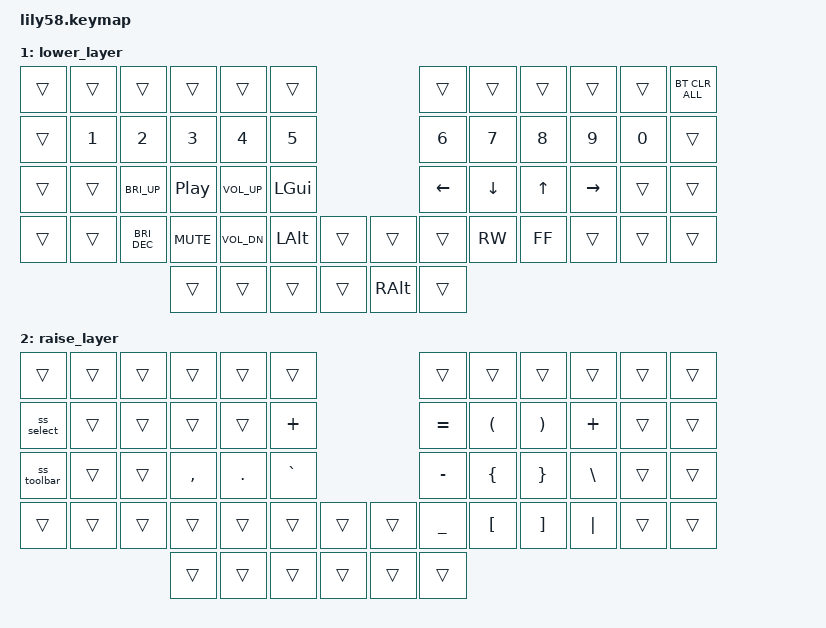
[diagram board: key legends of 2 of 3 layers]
/*
 * Lily58 keymap ported 1:1 from Corne
 */

#include <behaviors.dtsi>
#include <dt-bindings/zmk/bt.h>
#include <dt-bindings/zmk/keys.h>

/ {
    macros {
        ss_full: ss_full {
            compatible = "zmk,behavior-macro";
            label = "SS_FULL";
            #binding-cells = <0>;
            bindings = <&kp LC(LG(LS(N3)))>;
        };

        ss_select: ss_select {
            compatible = "zmk,behavior-macro";
            label = "SS_SELECT";
            #binding-cells = <0>;
            bindings = <&kp LG(LS(N4))>;
        };

        ss_toolbar: ss_toolbar {
            compatible = "zmk,behavior-macro";
            label = "SS_TOOLBAR";
            #binding-cells = <0>;
            bindings = <&kp LG(LS(N5))>;
        };

        ss_select_clip: ss_select_clip {
            compatible = "zmk,behavior-macro";
            label = "SS_SELECT_CLIP";
            #binding-cells = <0>;
            bindings = <&kp LC(LG(LS(N4)))>;
        };
    };

    keymap {
        compatible = "zmk,keymap";

        default_layer {
            bindings = <
&trans     &trans  &trans  &trans  &trans     &trans                         &trans    &trans  &trans     &trans   &trans    &trans
&kp TAB    &kp Q   &kp W   &kp E   &kp R      &kp T                          &kp Y     &kp U   &kp I      &kp O    &kp P     &kp BSPC
&kp ESC    &kp A   &kp S   &kp D   &kp F      &kp G                          &kp H     &kp J   &kp K      &kp L    &kp SEMI  &kp RET
&kp LSHFT  &kp Z   &kp X   &kp C   &kp V      &kp B     &trans    &trans     &kp N     &kp M   &kp COMMA  &kp DOT  &kp FSLH  &kp SQT
                           &trans  &kp LCTRL  &kp LGUI  &mo 1     &kp SPACE  &kp RGUI  &mo 2   &trans
            >;
        };

        lower_layer {
            bindings = <
&trans  &trans  &trans         &trans      &trans        &trans                        &trans    &trans    &trans    &trans     &trans  &bt BT_CLR_ALL
&trans  &kp N1  &kp N2         &kp N3      &kp N4        &kp N5                        &kp N6    &kp N7    &kp N8    &kp N9     &kp N0  &trans
&trans  &trans  &kp C_BRI_UP   &kp C_PP    &kp C_VOL_UP  &kp LGUI                      &kp LEFT  &kp DOWN  &kp UP    &kp RIGHT  &trans  &trans
&trans  &trans  &kp C_BRI_DEC  &kp K_MUTE  &kp C_VOL_DN  &kp LALT  &trans    &trans    &trans    &kp C_RW  &kp C_FF  &trans     &trans  &trans
                               &trans      &trans        &trans    &trans    &kp RALT  &trans
            >;
        };

        raise_layer {
            bindings = <
&trans       &trans  &trans  &trans     &trans      &trans                       &trans          &trans            &trans             &trans    &trans  &trans
&ss_select   &trans  &trans  &trans     &trans      &kp PLUS                     &kp EQUAL       &kp LPAR          &kp RPAR           &kp PLUS  &trans  &trans
&ss_toolbar  &trans  &trans  &kp COMMA  &kp PERIOD  &kp GRAVE                    &kp MINUS       &kp LBRC          &kp RBRC           &kp BSLH  &trans  &trans
&trans       &trans  &trans  &trans     &trans      &trans     &trans    &trans  &kp UNDERSCORE  &kp LEFT_BRACKET  &kp RIGHT_BRACKET  &kp PIPE  &trans  &trans
                             &trans     &trans      &trans     &trans    &trans  &trans
            >;

            sensor-bindings = <&inc_dec_kp C_VOL_UP C_VOL_DN>;
        };
    };
};
